# FUSB15200 register map
Vendor: ON Semiconductor; Series: FUSB15200; File version: 1.0
CPU: CM0+ r1p0, little endian, no MPU, no FPU, 3 interrupt priority bits
Registers are 32-bit, read-write, reset 0x0 unless marked. A register's access mark holds for its fields unless they carry their own. Offsets are from the block's base; [hi:lo] are bit positions; {n}, {i} and the like mark numbered series.

## Legacy_DP_DM_Protocol_Port_A
Base 0x41C00000
Same registers: Legacy_DP_DM_Protocol_Port_B 0x41D00000
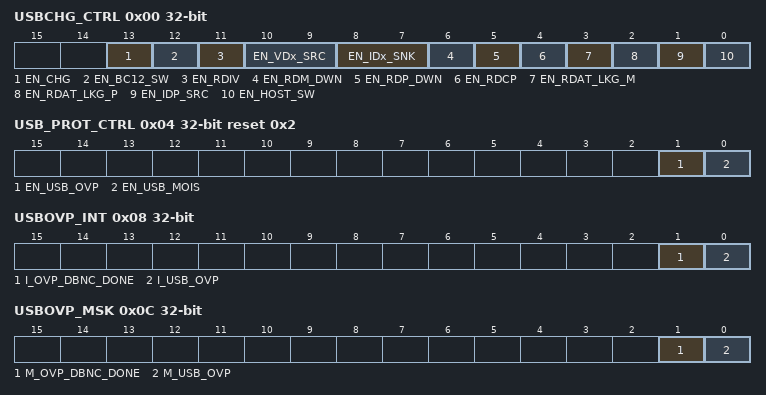
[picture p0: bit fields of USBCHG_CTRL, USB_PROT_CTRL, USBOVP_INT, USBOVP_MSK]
0x00 USBCHG_CTRL (reset mask 0x3AFF)
  [13] EN_CHG, [12] EN_BC12_SW, [11] EN_RDIV, [10:9] EN_VDx_SRC, [8:7] EN_IDx_SNK, [6] EN_RDM_DWN, [5] EN_RDP_DWN, [4] EN_RDCP, [3] EN_RDAT_LKG_M, [2] EN_RDAT_LKG_P, [1] EN_IDP_SRC, [0] EN_HOST_SW
0x04 USB_PROT_CTRL reset 0x2
  [1] EN_USB_OVP, [0] EN_USB_MOIS
0x08 USBOVP_INT
  [1] I_OVP_DBNC_DONE wo, [0] I_USB_OVP wo
0x0C USBOVP_MSK
  [1] M_OVP_DBNC_DONE, [0] M_USB_OVP

## Flash_Control
Base 0x41F00000
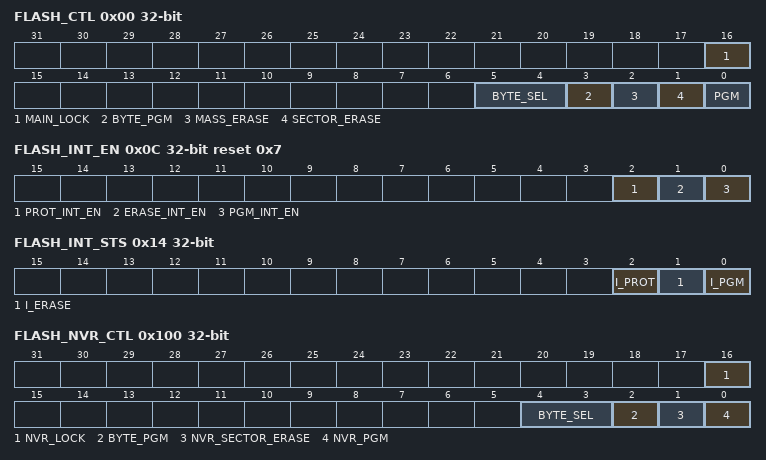
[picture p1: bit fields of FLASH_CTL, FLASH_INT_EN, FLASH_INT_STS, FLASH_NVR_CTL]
0x00 FLASH_CTL (reset mask 0x1001F)
  [16] MAIN_LOCK wo, [5:4] BYTE_SEL, [3] BYTE_PGM, [2] MASS_ERASE wo, [1] SECTOR_ERASE wo, [0] PGM wo
0x04 FLASH_ADDR (reset mask 0x1)
0x08 FLASH_DATA (reset mask 0x1)
0x0C FLASH_INT_EN reset 0x7
  [2] PROT_INT_EN, [1] ERASE_INT_EN, [0] PGM_INT_EN
0x14 FLASH_INT_STS
  [2] I_PROT wo, [1] I_ERASE wo, [0] I_PGM wo
{0x18+4i} FLASH_PROTO{i} (reset mask 0x1) (i=0..7)
0x38 FLASH_PROTO8 (reset mask 0x1)
  [7:0] FLASH_PROTO8
0xA0 FLASH_KEY_MAIN (reset mask 0x1)
  [31:0] FLASH_KEY_MAIN wo
0xA4 FLASH_KEY_NVR (reset mask 0x1)
  [31:0] FLASH_KEY_NVR wo
0x100 FLASH_NVR_CTL (reset mask 0x1000F)
  [16] NVR_LOCK wo, [4:3] BYTE_SEL, [2] BYTE_PGM, [1] NVR_SECTOR_ERASE wo, [0] NVR_PGM wo

## HPD_Port_A
Base 0x42300000
Same registers: HPD_Port_B 0x42400000
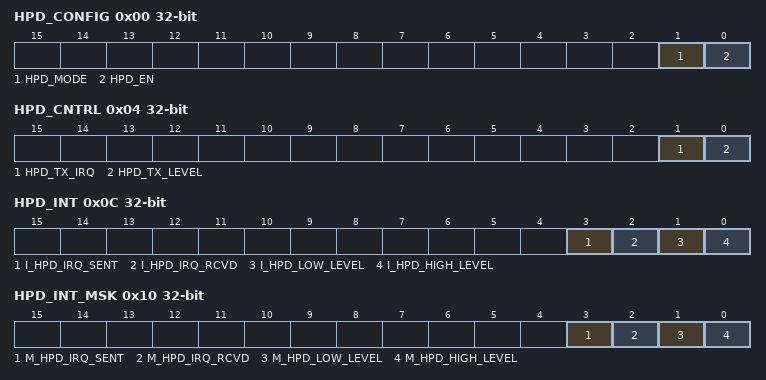
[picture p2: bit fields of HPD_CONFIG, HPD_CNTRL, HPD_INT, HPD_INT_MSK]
0x00 HPD_CONFIG
  [1] HPD_MODE, [0] HPD_EN
0x04 HPD_CNTRL
  [1] HPD_TX_IRQ wo, [0] HPD_TX_LEVEL
0x08 HPD_STS
  [0] HPD_IO_STATUS ro
0x0C HPD_INT
  [3] I_HPD_IRQ_SENT wo, [2] I_HPD_IRQ_RCVD wo, [1] I_HPD_LOW_LEVEL wo, [0] I_HPD_HIGH_LEVEL wo
0x10 HPD_INT_MSK
  [3] M_HPD_IRQ_SENT, [2] M_HPD_IRQ_RCVD, [1] M_HPD_LOW_LEVEL, [0] M_HPD_HIGH_LEVEL

## NVR1
Base 0x08000000
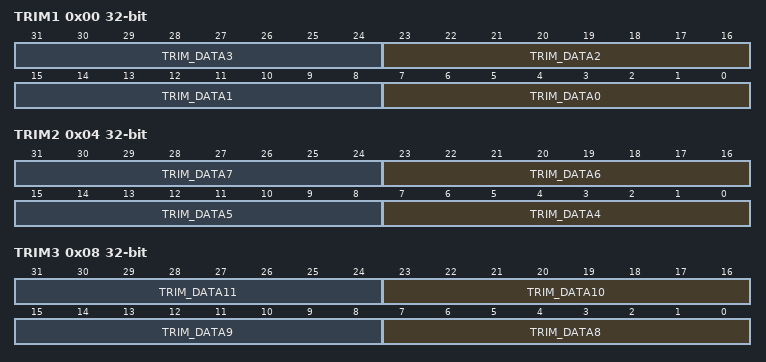
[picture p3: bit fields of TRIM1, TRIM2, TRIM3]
0x00 TRIM1 (reset mask 0x1010101)
  [8n+7:8n] TRIM_DATA{n} (n=0..3)
0x04 TRIM2 (reset mask 0x1010101)
  [8n-25:8n-32] TRIM_DATA{n} (n=4..7)
0x08 TRIM3 (reset mask 0x1010101)
  [8n-57:8n-64] TRIM_DATA{n} (n=8..11)

## NVR4
Base 0x08000600
0xFC SWD_LOCK (reset mask 0x1)
  [31:0] SWD_LOCK ro

## NVR5
Base 0x08000800
0x44 CP1_Good_Die reset 0xAA55 (reset mask 0x1)
  [15:0] CP1_GOOD_DIE ro
0x48 CP2_Good_Die reset 0xAA55 (reset mask 0x1)
  [15:0] CP2_GOOD_DIE ro

## SYSTICK_Timer_Registers
Base 0xE000E010
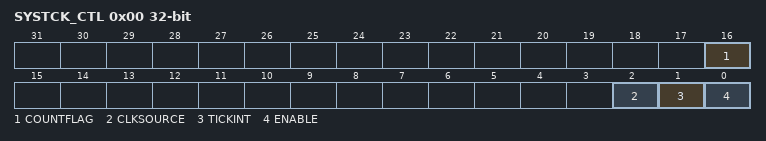
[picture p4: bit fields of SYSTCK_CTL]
0x00 SYSTCK_CTL
  [16] COUNTFLAG ro, [2] CLKSOURCE ro, [1] TICKINT, [0] ENABLE
0x04 SYSCTCK_RLD reset 0xFFFFFF (reset mask 0x1)
  [23:0] LOAD
0x08 SYSTCK_CNT reset 0xFFFFFF (reset mask 0x1)
  [23:0] CNT ro

## Nested_Vector_Interrupt_Controller
Base 0xE000E100
0x00 NVIC_ISER (reset mask 0x1)
  [31:0] SETENA
0x80 NVIC_ICER (reset mask 0x1)
  [31:0] CLRENA
0x100 NVIC_ISPR (reset mask 0x1)
  [31:0] SETPEND
0x180 NVIC_ICPR (reset mask 0x1)
  [31:0] CLRPEND
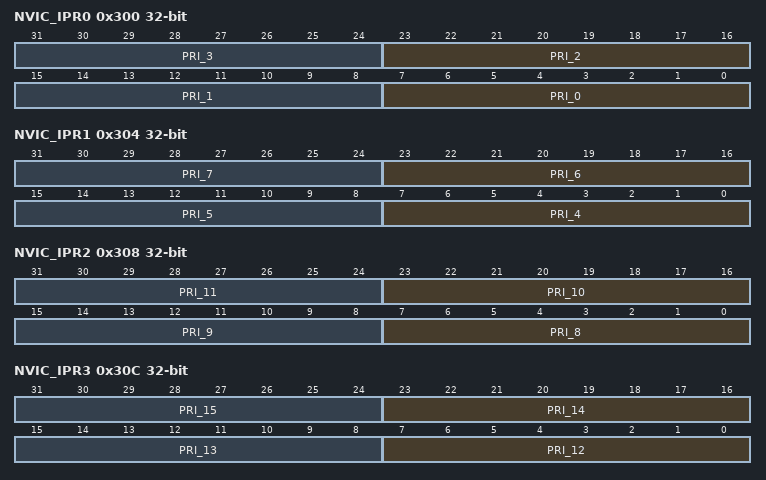
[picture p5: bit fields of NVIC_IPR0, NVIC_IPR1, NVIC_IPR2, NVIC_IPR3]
0x300 NVIC_IPR0 (reset mask 0x1010101)
  [8n+7:8n] PRI_{n} (n=0..3)
0x304 NVIC_IPR1 (reset mask 0x1010101)
  [8n-25:8n-32] PRI_{n} (n=4..7)
0x308 NVIC_IPR2 (reset mask 0x1010101)
  [8n-57:8n-64] PRI_{n} (n=8..11)
0x30C NVIC_IPR3 (reset mask 0x1010101)
  [8n-89:8n-96] PRI_{n} (n=12..15)
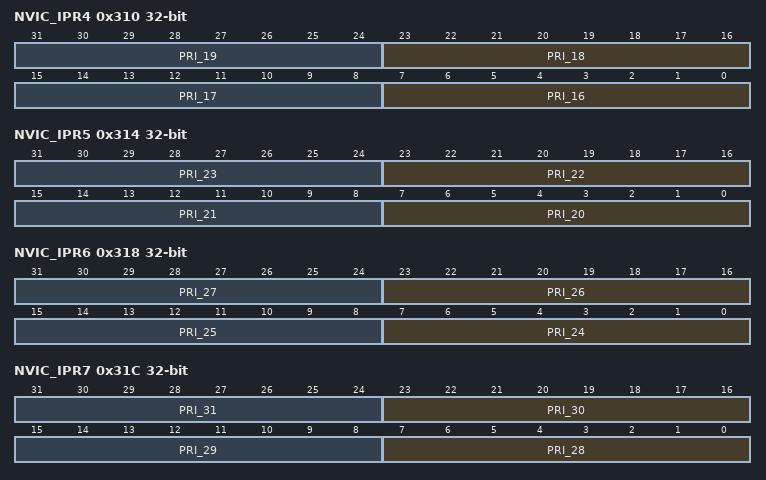
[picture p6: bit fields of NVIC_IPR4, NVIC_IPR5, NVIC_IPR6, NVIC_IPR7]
0x310 NVIC_IPR4 (reset mask 0x1010101)
  [8n-121:8n-128] PRI_{n} (n=16..19)
0x314 NVIC_IPR5 (reset mask 0x1010101)
  [8n-153:8n-160] PRI_{n} (n=20..23)
0x318 NVIC_IPR6 (reset mask 0x1010101)
  [8n-185:8n-192] PRI_{n} (n=24..27)
0x31C NVIC_IPR7 (reset mask 0x1010101)
  [8n-217:8n-224] PRI_{n} (n=28..31)

## System_Control_Block
Base 0xE000ED00
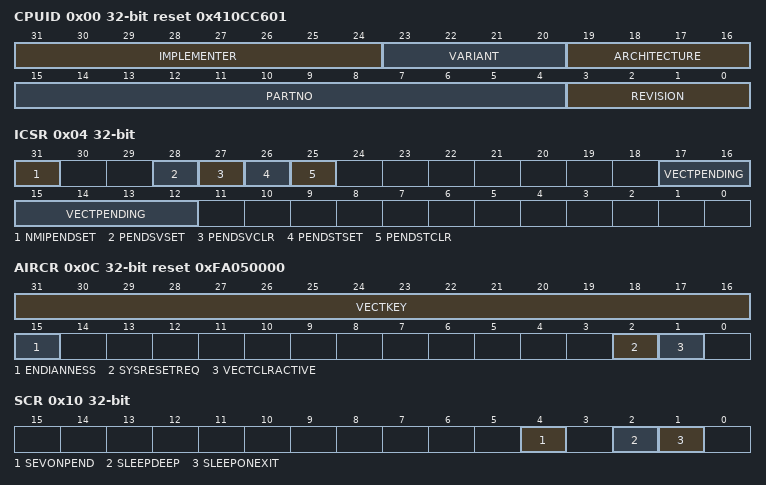
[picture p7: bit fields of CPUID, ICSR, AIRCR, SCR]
0x00 CPUID reset 0x410CC601 (reset mask 0x1110011)
  [31:24] IMPLEMENTER ro, [23:20] VARIANT ro, [19:16] ARCHITECTURE ro, [15:4] PARTNO ro, [3:0] REVISION ro
0x04 ICSR (reset mask 0x9E001000)
  [31] NMIPENDSET, [28] PENDSVSET, [27] PENDSVCLR wo, [26] PENDSTSET, [25] PENDSTCLR wo, [17:12] VECTPENDING ro
0x08 VTOR (reset mask 0x80)
  [31:7] TBLOFF
0x0C AIRCR reset 0xFA050000 (reset mask 0x18006)
  [31:16] VECTKEY, [15] ENDIANNESS ro, [2] SYSRESETREQ wo, [1] VECTCLRACTIVE wo
0x10 SCR
  [4] SEVONPEND, [2] SLEEPDEEP, [1] SLEEPONEXIT
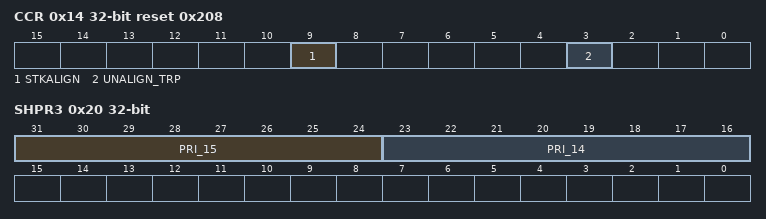
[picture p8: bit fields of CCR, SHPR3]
0x14 CCR reset 0x208
  [9] STKALIGN ro, [3] UNALIGN_TRP ro
0x1C SHPR2 (reset mask 0x1000000)
  [31:24] PRI_11
0x20 SHPR3 (reset mask 0x1010000)
  [31:24] PRI_15, [23:16] PRI_14
